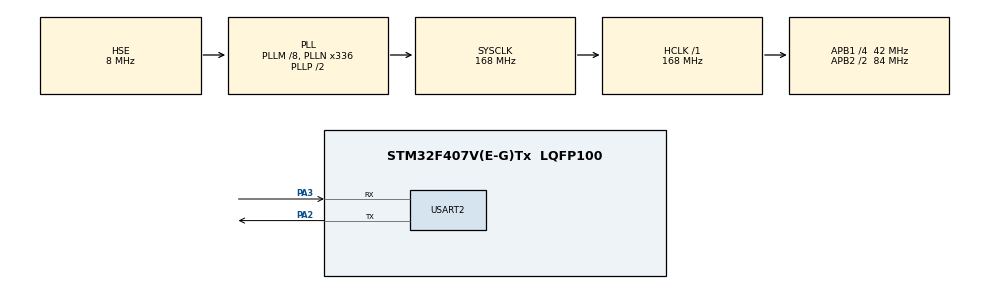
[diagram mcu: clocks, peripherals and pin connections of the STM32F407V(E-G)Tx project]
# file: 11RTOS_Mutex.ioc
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FREERTOS.Mutexes01=myMutex01,Dynamic,NULL,Available
FREERTOS.Tasks01=Task1,1,128,StartTask1,Default,NULL,Dynamic,NULL,NULL;Task2,0,128,StartTask2,Default,NULL,Dynamic,NULL,NULL;Task3,-1,128,StartTask3,Default,NULL,Dynamic,NULL,NULL
Mcu.Family=STM32F4
Mcu.Name=STM32F407V(E-G)Tx
Mcu.Package=LQFP100
NVIC.PriorityGroup=NVIC_PRIORITYGROUP_4
PA2.Mode=Asynchronous
PA2.Signal=USART2_TX
PA3.Mode=Asynchronous
PA3.Signal=USART2_RX
PH0-OSC_IN.Mode=HSE-External-Oscillator
PH0-OSC_IN.Signal=RCC_OSC_IN
PH1-OSC_OUT.Mode=HSE-External-Oscillator
PH1-OSC_OUT.Signal=RCC_OSC_OUT
ProjectManager.HeapSize=0x200
ProjectManager.StackSize=0x400
ProjectManager.TargetToolchain=STM32CubeIDE
RCC.48MHZClocksFreq_Value=48000000
RCC.AHBFreq_Value=168000000
RCC.APB1CLKDivider=RCC_HCLK_DIV4
RCC.APB1Freq_Value=42000000
RCC.APB1TimFreq_Value=84000000
RCC.APB2CLKDivider=RCC_HCLK_DIV2
RCC.APB2Freq_Value=84000000
RCC.APB2TimFreq_Value=168000000
RCC.CortexFreq_Value=168000000
RCC.HCLKFreq_Value=168000000
RCC.HSE_VALUE=8000000
RCC.HSI_VALUE=16000000
RCC.LSE_VALUE=32768
RCC.PLLM=8
RCC.PLLN=336
RCC.PLLQ=7
RCC.PLLSourceVirtual=RCC_PLLSOURCE_HSE
RCC.SYSCLKFreq_VALUE=168000000
RCC.SYSCLKSource=RCC_SYSCLKSOURCE_PLLCLK
RCC.VCOOutputFreq_Value=336000000
USART2.VirtualMode=VM_ASYNC
VP_FREERTOS_VS_CMSIS_V1.Mode=CMSIS_V1
board=STM32F407G-DISC1

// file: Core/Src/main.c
/* USER CODE BEGIN Header */
/**
  ******************************************************************************
  * @file           : main.c
  * @brief          : Main program body
  ******************************************************************************
  * @attention
  *
  * Copyright (c) 2026 STMicroelectronics.
  * All rights reserved.
  *
  * This software is licensed under terms that can be found in the LICENSE file
  * in the root directory of this software component.
  * If no LICENSE file comes with this software, it is provided AS-IS.
  *
  ******************************************************************************
  */
/* USER CODE END Header */
#include "main.h"
#include "cmsis_os.h"

/* USER CODE BEGIN Includes */
#include "stdio.h"
#include "string.h"
/* USER CODE END Includes */

UART_HandleTypeDef huart2;

osThreadId Task1Handle;
osThreadId Task2Handle;
osThreadId Task3Handle;
osMutexId myMutex01Handle;

void SystemClock_Config(void);
static void MX_GPIO_Init(void);
static void MX_USART2_UART_Init(void);
void StartTask1(void const * argument);
void StartTask2(void const * argument);
void StartTask3(void const * argument);

/* USER CODE BEGIN 0 */
void send_uart(char *msg)
{
    HAL_UART_Transmit(&huart2, (uint8_t*)msg, strlen(msg), HAL_MAX_DELAY);
}
/* USER CODE END 0 */

int main(void)
{

  /* MCU Configuration--------------------------------------------------------*/

  /* Reset of all peripherals, Initializes the Flash interface and the Systick. */
  HAL_Init();

  /* Configure the system clock */
  SystemClock_Config();

  /* Initialize all configured peripherals */
  MX_GPIO_Init();
  MX_USART2_UART_Init();

  /* Create the mutex(es) */
  /* definition and creation of myMutex01 */
  osMutexDef(myMutex01);
  myMutex01Handle = osMutexCreate(osMutex(myMutex01));

  /* USER CODE BEGIN RTOS_SEMAPHORES */
  /* add semaphores, ... */
  if (myMutex01Handle != NULL)
      {
          char str[] = "MUTEX CREATED\r\n";
          HAL_UART_Transmit(&huart2, (uint8_t*)str, strlen(str), HAL_MAX_DELAY);
      }

  /* USER CODE END RTOS_SEMAPHORES */

  /* Create the thread(s) */
  /* definition and creation of Task1 */
  osThreadDef(Task1, StartTask1, osPriorityAboveNormal, 0, 128);
  Task1Handle = osThreadCreate(osThread(Task1), NULL);

  /* definition and creation of Task2 */
  osThreadDef(Task2, StartTask2, osPriorityNormal, 0, 128);
  Task2Handle = osThreadCreate(osThread(Task2), NULL);

  /* definition and creation of Task3 */
  osThreadDef(Task3, StartTask3, osPriorityBelowNormal, 0, 128);
  Task3Handle = osThreadCreate(osThread(Task3), NULL);

  /* Start scheduler */
  osKernelStart();

  /* We should never get here as control is now taken by the scheduler */

  /* Infinite loop */
  while (1)
  {

  }
}

void SystemClock_Config(void)
{
  RCC_OscInitTypeDef RCC_OscInitStruct = {0};
  RCC_ClkInitTypeDef RCC_ClkInitStruct = {0};

  /** Configure the main internal regulator output voltage
  */
  __HAL_RCC_PWR_CLK_ENABLE();
  __HAL_PWR_VOLTAGESCALING_CONFIG(PWR_REGULATOR_VOLTAGE_SCALE1);

  /** Initializes the RCC Oscillators according to the specified parameters
  * in the RCC_OscInitTypeDef structure.
  */
  RCC_OscInitStruct.OscillatorType = RCC_OSCILLATORTYPE_HSE;
  RCC_OscInitStruct.HSEState = RCC_HSE_ON;
  RCC_OscInitStruct.PLL.PLLState = RCC_PLL_ON;
  RCC_OscInitStruct.PLL.PLLSource = RCC_PLLSOURCE_HSE;
  RCC_OscInitStruct.PLL.PLLM = 8;
  RCC_OscInitStruct.PLL.PLLN = 336;
  RCC_OscInitStruct.PLL.PLLP = RCC_PLLP_DIV2;
  RCC_OscInitStruct.PLL.PLLQ = 7;
  if (HAL_RCC_OscConfig(&RCC_OscInitStruct) != HAL_OK)
  {
    Error_Handler();
  }

  /** Initializes the CPU, AHB and APB buses clocks
  */
  RCC_ClkInitStruct.ClockType = RCC_CLOCKTYPE_HCLK|RCC_CLOCKTYPE_SYSCLK
                              |RCC_CLOCKTYPE_PCLK1|RCC_CLOCKTYPE_PCLK2;
  RCC_ClkInitStruct.SYSCLKSource = RCC_SYSCLKSOURCE_PLLCLK;
  RCC_ClkInitStruct.AHBCLKDivider = RCC_SYSCLK_DIV1;
  RCC_ClkInitStruct.APB1CLKDivider = RCC_HCLK_DIV4;
  RCC_ClkInitStruct.APB2CLKDivider = RCC_HCLK_DIV2;

  if (HAL_RCC_ClockConfig(&RCC_ClkInitStruct, FLASH_LATENCY_5) != HAL_OK)
  {
    Error_Handler();
  }
}

static void MX_USART2_UART_Init(void)
{

  huart2.Instance = USART2;
  huart2.Init.BaudRate = 115200;
  huart2.Init.WordLength = UART_WORDLENGTH_8B;
  huart2.Init.StopBits = UART_STOPBITS_1;
  huart2.Init.Parity = UART_PARITY_NONE;
  huart2.Init.Mode = UART_MODE_TX_RX;
  huart2.Init.HwFlowCtl = UART_HWCONTROL_NONE;
  huart2.Init.OverSampling = UART_OVERSAMPLING_16;
  if (HAL_UART_Init(&huart2) != HAL_OK)
  {
    Error_Handler();
  }

}

static void MX_GPIO_Init(void)
{

  /* GPIO Ports Clock Enable */
  __HAL_RCC_GPIOH_CLK_ENABLE();
  __HAL_RCC_GPIOA_CLK_ENABLE();

}

void StartTask1(void const * argument)
{
  /* USER CODE BEGIN 5 */
  /* Infinite loop */
	char *strtosend = "IN HPT -----------------------\r\n";

	    for (;;)
	    {
	        // Acquire mutex before accessing shared resource (UART)
	        osMutexWait(myMutex01Handle, osWaitForever);

	        send_uart("ENTERED HPT\r\n");
	        send_uart(strtosend);
	        send_uart("LEFT HPT\r\n");

	        osMutexRelease(myMutex01Handle);

	        // FIX 4: Single delay, removed duplicate osDelay(1)
	        osDelay(1000);
	    }
  /* USER CODE END 5 */
}

void StartTask2(void const * argument)
{
  /* USER CODE BEGIN StartTask2 */
  /* Infinite loop */
	char *strtosend = "IN MTP -----------------------\r\n";

	    for (;;)
	    {
	        osMutexWait(myMutex01Handle, osWaitForever);

	        // FIX 6: Corrected strings from "HPT" to "MTP"
	        send_uart("ENTERED MTP\r\n");
	        send_uart(strtosend);
	        send_uart("LEFT MTP\r\n");

	        osMutexRelease(myMutex01Handle);

	        osDelay(1000);
	    }
  /* USER CODE END StartTask2 */
}

void StartTask3(void const * argument)
{
  /* USER CODE BEGIN StartTask3 */
  /* Infinite loop */
	char *strtosend = "IN LTP -----------------------\r\n";

		    for (;;)
		    {
		        osMutexWait(myMutex01Handle, osWaitForever);

		        // FIX 7: Task3 was completely empty — now does something useful
		        send_uart("ENTERED LTP\r\n");
		        send_uart(strtosend);
		        send_uart("LEFT LTP\r\n");

		        osMutexRelease(myMutex01Handle);

		        osDelay(1000);
		    }
  /* USER CODE END StartTask3 */
}

void Error_Handler(void)
{
  __disable_irq();
  while (1)
  {
  }
}
